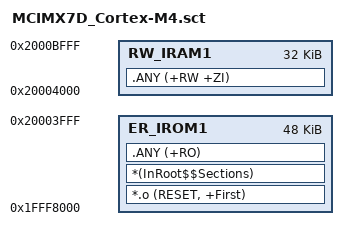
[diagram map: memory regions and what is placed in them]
; *********************************************************************
; ** Scatter-Loading Description File generated by RTE CMSIS Plug-in **
; *********************************************************************

LR_IROM1 0x1FFF8000 0x0000C000 {    ; load region size_region
  ER_IROM1 0x1FFF8000 0x0000C000 {  ; load address = execution address
   *.o (RESET, +First)
   *(InRoot$$Sections)
   .ANY (+RO)
  }
  RW_IRAM1 0x20004000 0x00008000 {
   .ANY (+RW +ZI)
  }
}

